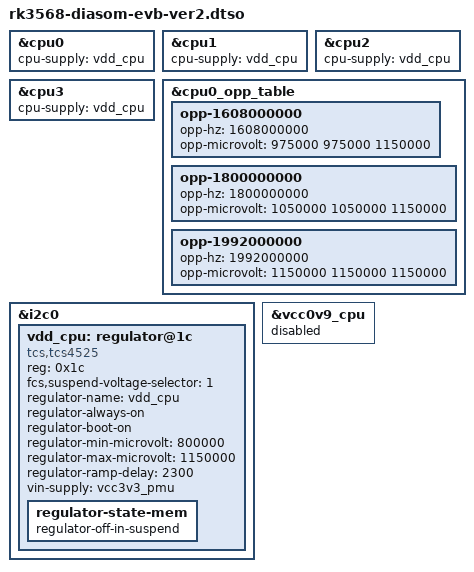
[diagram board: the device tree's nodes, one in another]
/* SPDX-License-Identifier: GPL-2.0+ */
/* SPDX-FileCopyrightText: Alexander Shiyan <shc_work@mail.ru> */

/dts-v1/;
/plugin/;

&cpu0 {
	cpu-supply = <&vdd_cpu>;
};

&cpu1 {
	cpu-supply = <&vdd_cpu>;
};

&cpu2 {
	cpu-supply = <&vdd_cpu>;
};

&cpu3 {
	cpu-supply = <&vdd_cpu>;
};

&cpu0_opp_table {
	opp-1608000000 {
		opp-hz = /bits/ 64 <1608000000>;
		opp-microvolt = <975000 975000 1150000>;
	};
	
	opp-1800000000 {
		opp-hz = /bits/ 64 <1800000000>;
		opp-microvolt = <1050000 1050000 1150000>;
	};

	opp-1992000000 {
		opp-hz = /bits/ 64 <1992000000>;
		opp-microvolt = <1150000 1150000 1150000>;
	};
};

&i2c0 {
	vdd_cpu: regulator@1c {
		compatible = "tcs,tcs4525";
		reg = <0x1c>;
		fcs,suspend-voltage-selector = <1>;
		regulator-name = "vdd_cpu";
		regulator-always-on;
		regulator-boot-on;
		regulator-min-microvolt = <800000>;
		regulator-max-microvolt = <1150000>;
		regulator-ramp-delay = <2300>;
		vin-supply = <&vcc3v3_pmu>;
		
		regulator-state-mem {
			regulator-off-in-suspend;
		};
	};
};

&vcc0v9_cpu {
	status = "disabled";
};
